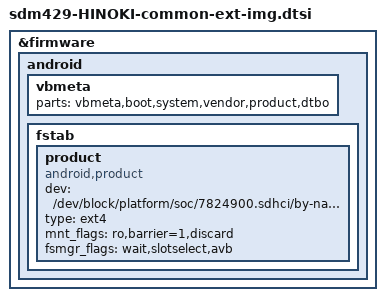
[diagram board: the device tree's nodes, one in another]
/*
 * This software is contributed or developed by KYOCERA Corporation.
 * (C) 2019 KYOCERA Corporation
 *
 * Copyright (c) 2015-2018, The Linux Foundation. All rights reserved.
 *
 * This program is free software; you can redistribute it and/or modify
 * it under the terms of the GNU General Public License version 2 and
 * only version 2 as published by the Free Software Foundation.
 *
 * This program is distributed in the hope that it will be useful,
 * but WITHOUT ANY WARRANTY; without even the implied warranty of
 * MERCHANTABILITY or FITNESS FOR A PARTICULAR PURPOSE.  See the
 * GNU General Public License for more details.
 */

	&firmware {
		android {
			vbmeta {
				parts = "vbmeta,boot,system,vendor,product,dtbo";
			};

			fstab {
				product {
					compatible = "android,product";
					dev = "/dev/block/platform/soc/7824900.sdhci/by-name/product";
					type = "ext4";
					mnt_flags = "ro,barrier=1,discard";
					fsmgr_flags = "wait,slotselect,avb";
					status = "ok";
				};
			};
		};
	};
